# HDSC_HC32L072KATA register map
Vendor: HDSC Co.Ltd; Series: ARMCM0P; File version: 1.2
CPU: CM0 r0p0, little endian, no MPU, no FPU, 3 interrupt priority bits
Registers are 32-bit, read-write, reset 0x0 unless marked. A register's access mark holds for its fields unless they carry their own. Offsets are from the block's base; [hi:lo] are bit positions; {n}, {i} and the like mark numbered series.

## AES
Base 0x40021400
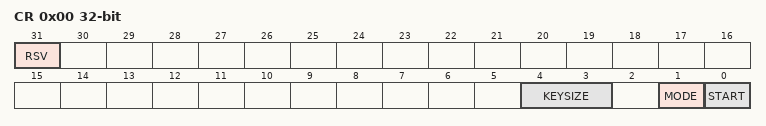
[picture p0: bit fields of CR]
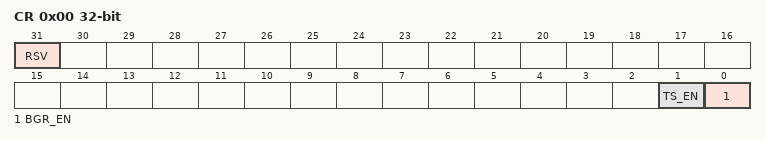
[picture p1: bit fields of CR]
0x00 CR (reset mask 0x3)
  [31] RSV, [4:3] KEYSIZE, [1] MODE, [0] START
0x10 DATA0
{0x10+4i} DATA{i} (i=1..3)
  [31:0] DATA0
0x20 KEY0
{0x20+4i} KEY{i} (i=1..7)
  [31:0] KEY0

## BGR
Base 0x40002400; alternate view of ADC
0x00 CR (reset mask 0x3)
  [31] RSV, [1] TS_EN, [0] BGR_EN

## CAN
Base 0x40030000
{0x0+4i} RBUF{i} ro (i=0..3)
{0x50+4i} TBUF{i} (i=0..3)
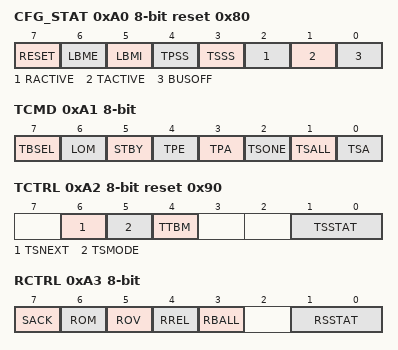
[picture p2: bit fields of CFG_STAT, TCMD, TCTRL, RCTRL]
0xA0 CFG_STAT 8-bit reset 0x80
  [7] RESET, [6] LBME, [5] LBMI, [4] TPSS, [3] TSSS, [2] RACTIVE ro, [1] TACTIVE ro, [0] BUSOFF
0xA1 TCMD 8-bit
  [7] TBSEL, [6] LOM, [5] STBY, [4] TPE, [3] TPA, [2] TSONE, [1] TSALL, [0] TSA
0xA2 TCTRL 8-bit reset 0x90
  [6] TSNEXT, [5] TSMODE, [4] TTBM, [1:0] TSSTAT ro
0xA3 RCTRL 8-bit
  [7] SACK, [6] ROM, [5] ROV ro, [4] RREL, [3] RBALL, [1:0] RSSTAT ro
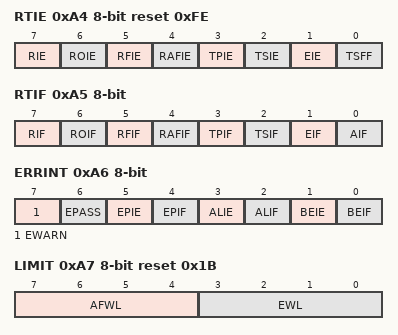
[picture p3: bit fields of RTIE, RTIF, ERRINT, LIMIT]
0xA4 RTIE 8-bit reset 0xFE
  [7] RIE, [6] ROIE, [5] RFIE, [4] RAFIE, [3] TPIE, [2] TSIE, [1] EIE, [0] TSFF ro
0xA5 RTIF 8-bit
  [7] RIF, [6] ROIF, [5] RFIF, [4] RAFIF, [3] TPIF, [2] TSIF, [1] EIF, [0] AIF
0xA6 ERRINT 8-bit
  [7] EWARN ro, [6] EPASS ro, [5] EPIE, [4] EPIF, [3] ALIE, [2] ALIF, [1] BEIE, [0] BEIF
0xA7 LIMIT 8-bit reset 0x1B
  [7:4] AFWL, [3:0] EWL
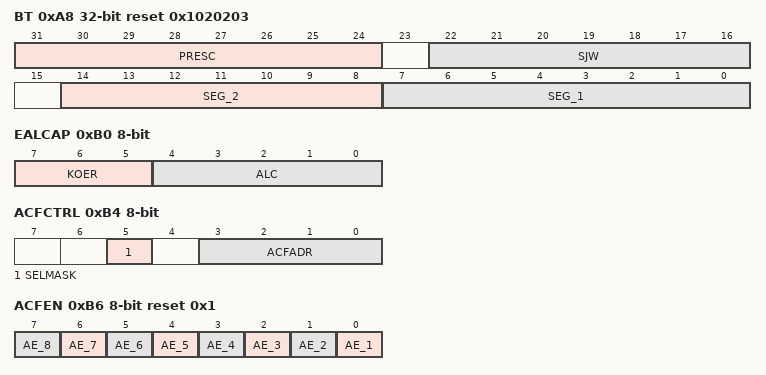
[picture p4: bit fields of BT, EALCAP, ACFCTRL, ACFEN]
0xA8 BT reset 0x1020203
  [31:24] PRESC, [22:16] SJW, [14:8] SEG_2, [7:0] SEG_1
0xB0 EALCAP 8-bit ro
  [7:5] KOER, [4:0] ALC
0xB2 RECNT 8-bit
0xB3 TECNT 8-bit
0xB4 ACFCTRL 8-bit
  [5] SELMASK, [3:0] ACFADR
0xB6 ACFEN 8-bit reset 0x1
  [n-1] AE_{n} (n=1..8)
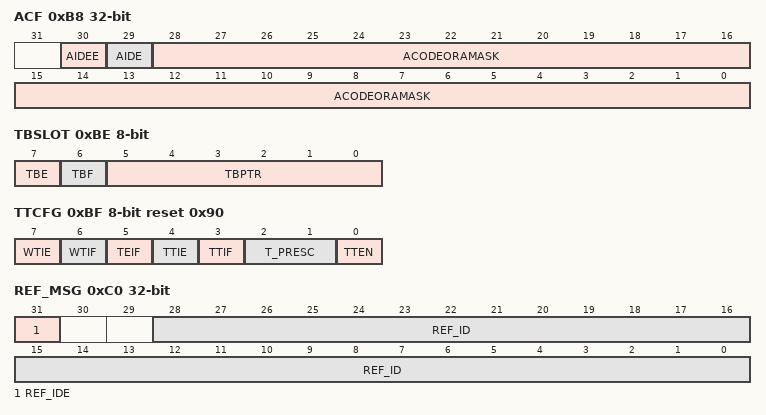
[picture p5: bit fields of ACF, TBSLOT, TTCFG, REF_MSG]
0xB8 ACF
  [30] AIDEE, [29] AIDE, [28:0] ACODEORAMASK
0xBE TBSLOT 8-bit
  [7] TBE, [6] TBF, [5:0] TBPTR
0xBF TTCFG 8-bit reset 0x90
  [7] WTIE, [6] WTIF, [5] TEIF, [4] TTIE, [3] TTIF, [2:1] T_PRESC, [0] TTEN
0xC0 REF_MSG
  [31] REF_IDE, [28:0] REF_ID
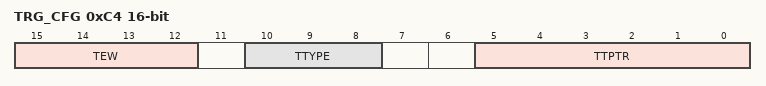
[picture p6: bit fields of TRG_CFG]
0xC4 TRG_CFG 16-bit
  [15:12] TEW, [10:8] TTYPE, [5:0] TTPTR
0xC6 TT_TRIG 16-bit
0xC8 TT_WTRIG 16-bit reset 0xFFFF

## CLK_TRIM
Base 0x40001800
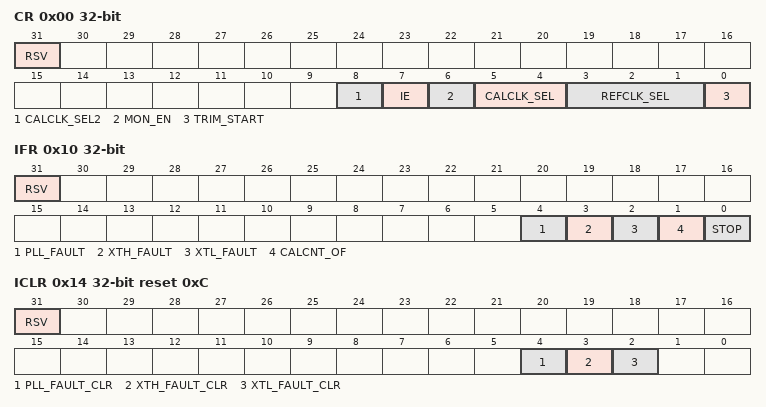
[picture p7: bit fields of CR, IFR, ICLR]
0x00 CR (reset mask 0xFF)
  [31] RSV, [8] CALCLK_SEL2, [7] IE, [6] MON_EN, [5:4] CALCLK_SEL, [3:1] REFCLK_SEL, [0] TRIM_START
0x04 REFCON
  [31:0] RCNTVAL
0x08 REFCNT ro
0x0C CALCNT ro
0x10 IFR ro (reset mask 0xF)
  [31] RSV, [4] PLL_FAULT, [3] XTH_FAULT, [2] XTL_FAULT, [1] CALCNT_OF, [0] STOP
0x14 ICLR reset 0xC (reset mask 0xC)
  [31] RSV, [4] PLL_FAULT_CLR, [3] XTH_FAULT_CLR, [2] XTL_FAULT_CLR
0x18 CALCON reset 0xFFFFFFFF
  [31:0] CCNTVAL

## CRC
Base 0x40020900
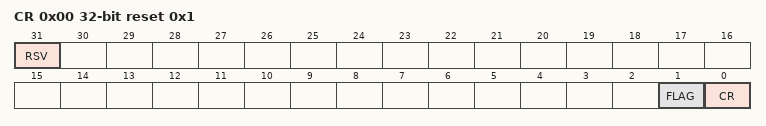
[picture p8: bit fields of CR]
0x00 CR reset 0x1 (reset mask 0x3)
  [31] RSV ro, [1] FLAG ro, [0] CR
0x04 RESULT
0x80 DATA wo

## CTS
Base 0x40005000
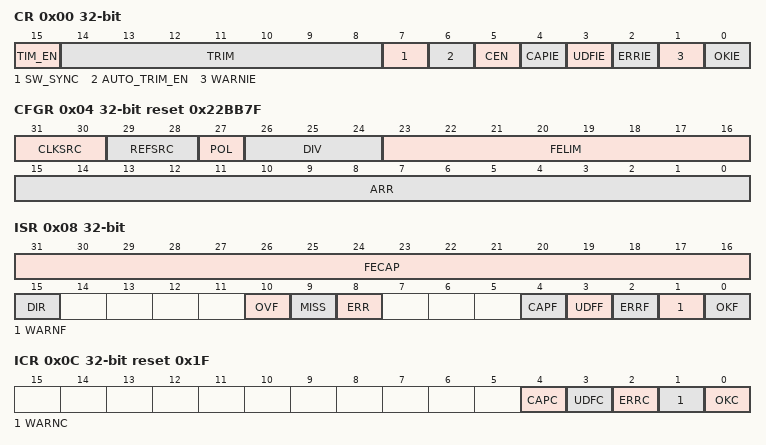
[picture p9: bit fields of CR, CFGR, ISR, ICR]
0x00 CR (reset mask 0xFFFF00FF)
  [15] TIM_EN, [14:8] TRIM, [7] SW_SYNC, [6] AUTO_TRIM_EN, [5] CEN, [4] CAPIE, [3] UDFIE, [2] ERRIE, [1] WARNIE, [0] OKIE
0x04 CFGR reset 0x22BB7F
  [31:30] CLKSRC, [29:28] REFSRC, [27] POL, [26:24] DIV, [23:16] FELIM, [15:0] ARR
0x08 ISR
  [31:16] FECAP, [15] DIR, [10] OVF, [9] MISS, [8] ERR, [4] CAPF, [3] UDFF, [2] ERRF, [1] WARNF, [0] OKF
0x0C ICR reset 0x1F
  [4] CAPC, [3] UDFC, [2] ERRC, [1] WARNC, [0] OKC

## DAC
Base 0x40002500
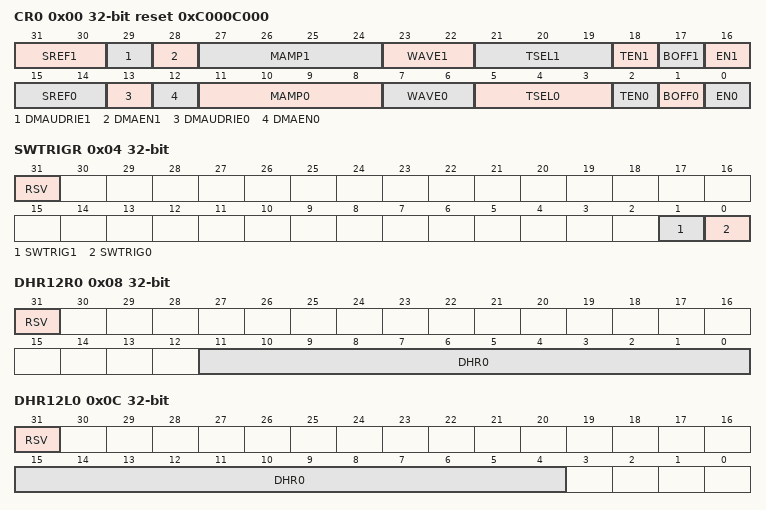
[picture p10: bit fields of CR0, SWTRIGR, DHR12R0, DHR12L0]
0x00 CR0 reset 0xC000C000
  [31:30] SREF1, [29] DMAUDRIE1, [28] DMAEN1, [27:24] MAMP1, [23:22] WAVE1, [21:19] TSEL1, [18] TEN1, [17] BOFF1, [16] EN1, [15:14] SREF0, [13] DMAUDRIE0, [12] DMAEN0, [11:8] MAMP0, [7:6] WAVE0, [5:3] TSEL0, [2] TEN0, [1] BOFF0, [0] EN0
0x04 SWTRIGR wo (reset mask 0x3)
  [31] RSV rw, [1] SWTRIG1, [0] SWTRIG0
0x08 DHR12R0 (reset mask 0xFFF)
  [31] RSV, [11:0] DHR0
0x0C DHR12L0 (reset mask 0xFFF0)
  [31] RSV, [15:4] DHR0
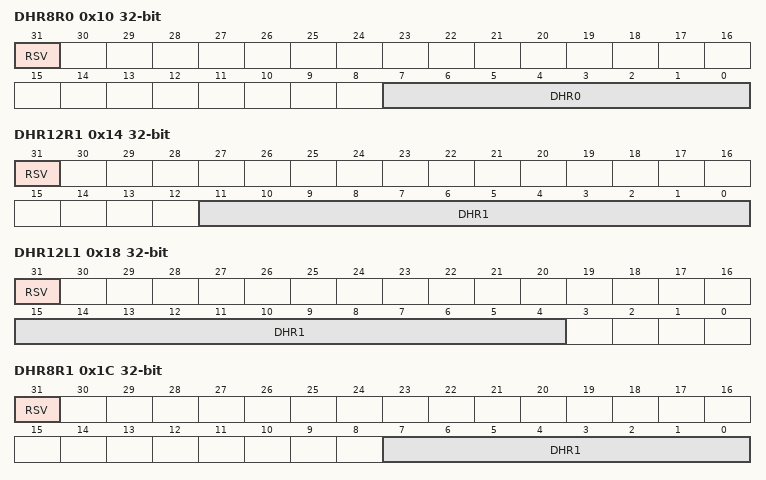
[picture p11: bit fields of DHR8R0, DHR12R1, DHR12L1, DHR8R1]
0x10 DHR8R0 (reset mask 0xFF)
  [31] RSV, [7:0] DHR0
0x14 DHR12R1 (reset mask 0xFFF)
  [31] RSV, [11:0] DHR1
0x18 DHR12L1 (reset mask 0xFFF0)
  [31] RSV, [15:4] DHR1
0x1C DHR8R1 (reset mask 0xFF)
  [31] RSV, [7:0] DHR1
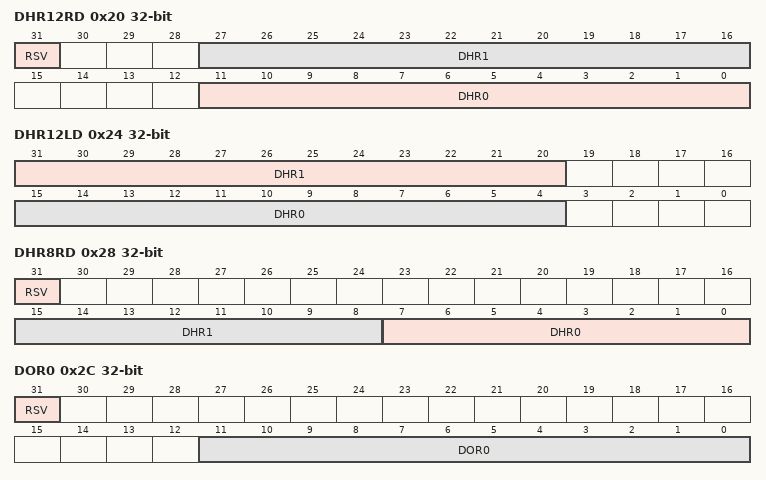
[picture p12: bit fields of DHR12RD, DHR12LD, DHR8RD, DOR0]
0x20 DHR12RD (reset mask 0xFFF0FFF)
  [31] RSV, [27:16] DHR1, [11:0] DHR0
0x24 DHR12LD
  [31:20] DHR1, [15:4] DHR0
0x28 DHR8RD (reset mask 0xFFFF)
  [31] RSV, [15:8] DHR1, [7:0] DHR0
0x2C DOR0 ro (reset mask 0xFFF)
  [31] RSV rw, [11:0] DOR0
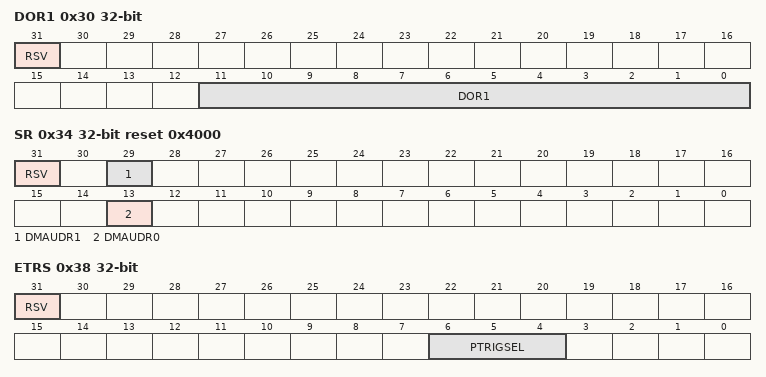
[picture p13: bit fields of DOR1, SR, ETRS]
0x30 DOR1 ro (reset mask 0xFFF)
  [31] RSV rw, [11:0] DOR1
0x34 SR reset 0x4000 (reset mask 0x20002000)
  [31] RSV, [29] DMAUDR1, [13] DMAUDR0
0x38 ETRS (reset mask 0x70)
  [31] RSV, [6:4] PTRIGSEL
